# MKV56F22 register map
Vendor: Freescale Semiconductor, Inc.; Series: Kinetis_V; File version: 1.6
CPU: CM7 r0p1, little endian, no MPU, FPU, VTOR, 4 interrupt priority bits
Registers are 32-bit, read-write, reset 0x0 unless marked. A register's access mark holds for its fields unless they carry their own. Offsets are from the block's base; [hi:lo] are bit positions; {n}, {i} and the like mark numbered series.

## FMC — Flash Memory Controller
Base 0x4001F000; register names take the prefix FMC_
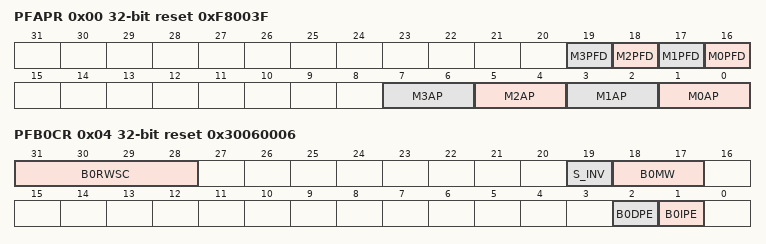
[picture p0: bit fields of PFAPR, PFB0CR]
0x00 PFAPR reset 0xF8003F — Flash Access Protection Register
  [n+16] M{n}PFD (n=0..3) — Master {n} Prefetch Disable
    0=Prefetching for this master is enabled; 1=Prefetching for this master is disabled
  [2n+1:2n] M{n}AP (n=0..3) — Master {n} Access Protection
    0=No access may be performed by this master; 1=Only read accesses may be performed by this master; 2=Only write accesses may be performed by this master; 3=Both read and write accesses may be performed by this master
0x04 PFB0CR reset 0x30060006 — Flash Bank 0 Control Register
  [31:28] B0RWSC ro — Bank 0 Read Wait State Control
  [19] S_INV wo — Invalidate Prefetch Speculation Buffer
    0=Speculation buffer is not affected; 1=Invalidate (clear) the speculation buffer
  [18:17] B0MW ro — Bank 0 Memory Width
    0=32 bits; 1=64 bits; 2=128 bits; 3=256 bits
  [2] B0DPE — Bank 0 Data Prefetch Enable
    0=Do not prefetch in response to data references; 1=Enable prefetches in response to data references
  [1] B0IPE — Bank 0 Instruction Prefetch Enable
    0=Do not prefetch in response to instruction fetches; 1=Enable prefetches in response to instruction fetches

## FTFE — Flash Memory Interface
Base 0x40020000; register names take the prefix FTFE_
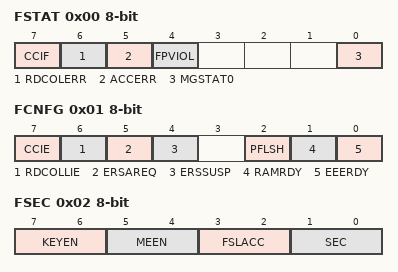
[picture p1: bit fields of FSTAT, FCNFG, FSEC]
0x00 FSTAT 8-bit — Flash Status Register
  [7] CCIF — Command Complete Interrupt Flag
    0=FTFE command in progress; 1=FTFE command has completed
  [6] RDCOLERR — FTFE Read Collision Error Flag
    0=No collision error detected; 1=Collision error detected
  [5] ACCERR — Flash Access Error Flag
    0=No access error detected; 1=Access error detected
  [4] FPVIOL — Flash Protection Violation Flag
    0=No protection violation detected; 1=Protection violation detected
  [0] MGSTAT0 ro — Memory Controller Command Completion Status Flag
0x01 FCNFG 8-bit — Flash Configuration Register
  [7] CCIE — Command Complete Interrupt Enable
    0=Command complete interrupt disabled; 1=Command complete interrupt enabled. An interrupt request is generated whenever the FSTAT[CCIF] flag is set.
  [6] RDCOLLIE — Read Collision Error Interrupt Enable
    0=Read collision error interrupt disabled; 1=Read collision error interrupt enabled. An interrupt request is generated whenever an FTFE read collision error is detected (see the description of FSTAT[RDCOLERR]).
  [5] ERSAREQ ro — Erase All Request
    0=No request or request complete; 1=Request to: run the Erase All Blocks command, verify the erased state, program the security byte in the Flash Configuration Field to the unsecure state, and release MCU security by setting the FSEC[SEC] field to the unsecure state
  [4] ERSSUSP — Erase Suspend
    0=No suspend requested; 1=Suspend the current Erase Flash Sector command execution
  [2] PFLSH ro — FTFE configuration
    1=FTFE configuration supports one program flash block
  [1] RAMRDY ro — RAM Ready
    0=Programming acceleration RAM is not available; 1=Programming acceleration RAM is available
  [0] EEERDY ro — This bit is reserved and always has the value 0.
    0=See RAMRDY for availability of programming acceleration RAM
0x02 FSEC 8-bit ro reset not defined — Flash Security Register
  [7:6] KEYEN — Backdoor Key Security Enable
    0=Backdoor key access disabled; 1=Backdoor key access disabled (preferred KEYEN state to disable backdoor key access); 2=Backdoor key access enabled; 3=Backdoor key access disabled
  [5:4] MEEN — Mass Erase Enable Bits
    0=Mass erase is enabled; 1=Mass erase is enabled; 2=Mass erase is disabled; 3=Mass erase is enabled
  [3:2] FSLACC — Freescale Failure Analysis Access Code
    0=Freescale factory access granted; 1=Freescale factory access denied; 2=Freescale factory access denied; 3=Freescale factory access granted
  [1:0] SEC — Flash Security
    0=MCU security status is secure; 1=MCU security status is secure; 2=MCU security status is unsecure (The standard shipping condition of the FTFE is unsecure.); 3=MCU security status is secure
0x03 FOPT 8-bit ro reset not defined — Flash Option Register
  [7:0] OPT — Nonvolatile Option
0x04 FCCOB{x} (x=3,2,1,0,7,6,5,4,B,A,9,8; step 0x1) 8-bit — Flash Common Command Object Registers
  [7:0] CCOBn — The FCCOB register provides a command code and relevant parameters to the memory controller
0x10 FPROT{x} (x=3,2,1,0; step 0x1) 8-bit reset not defined — Program Flash Protection Registers
  [7:0] PROT — Program Flash Region Protect
    0=Program flash region is protected; 1=Program flash region is not protected

## Notices in the file
Redistribution and use in source and binary forms, with or without modification,
are permitted provided that the following conditions are met:
o Redistributions of source code must retain the above copyright notice, this list
of conditions and the following disclaimer.
o Redistributions in binary form must reproduce the above copyright notice, this
list of conditions and the following disclaimer in the documentation and/or
other materials provided with the distribution.
o Neither the name of Freescale Semiconductor, Inc. nor the names of its
contributors may be used to endorse or promote products derived from this
software without specific prior written permission.
THIS SOFTWARE IS PROVIDED BY THE COPYRIGHT HOLDERS AND CONTRIBUTORS "AS IS" AND
ANY EXPRESS OR IMPLIED WARRANTIES, INCLUDING, BUT NOT LIMITED TO, THE IMPLIED
WARRANTIES OF MERCHANTABILITY AND FITNESS FOR A PARTICULAR PURPOSE ARE
DISCLAIMED. IN NO EVENT SHALL THE COPYRIGHT HOLDER OR CONTRIBUTORS BE LIABLE FOR
ANY DIRECT, INDIRECT, INCIDENTAL, SPECIAL, EXEMPLARY, OR CONSEQUENTIAL DAMAGES
(INCLUDING, BUT NOT LIMITED TO, PROCUREMENT OF SUBSTITUTE GOODS OR SERVICES;
LOSS OF USE, DATA, OR PROFITS; OR BUSINESS INTERRUPTION) HOWEVER CAUSED AND ON
ANY THEORY OF LIABILITY, WHETHER IN CONTRACT, STRICT LIABILITY, OR TORT
(INCLUDING NEGLIGENCE OR OTHERWISE) ARISING IN ANY WAY OUT OF THE USE OF THIS
SOFTWARE, EVEN IF ADVISED OF THE POSSIBILITY OF SUCH DAMAGE.
